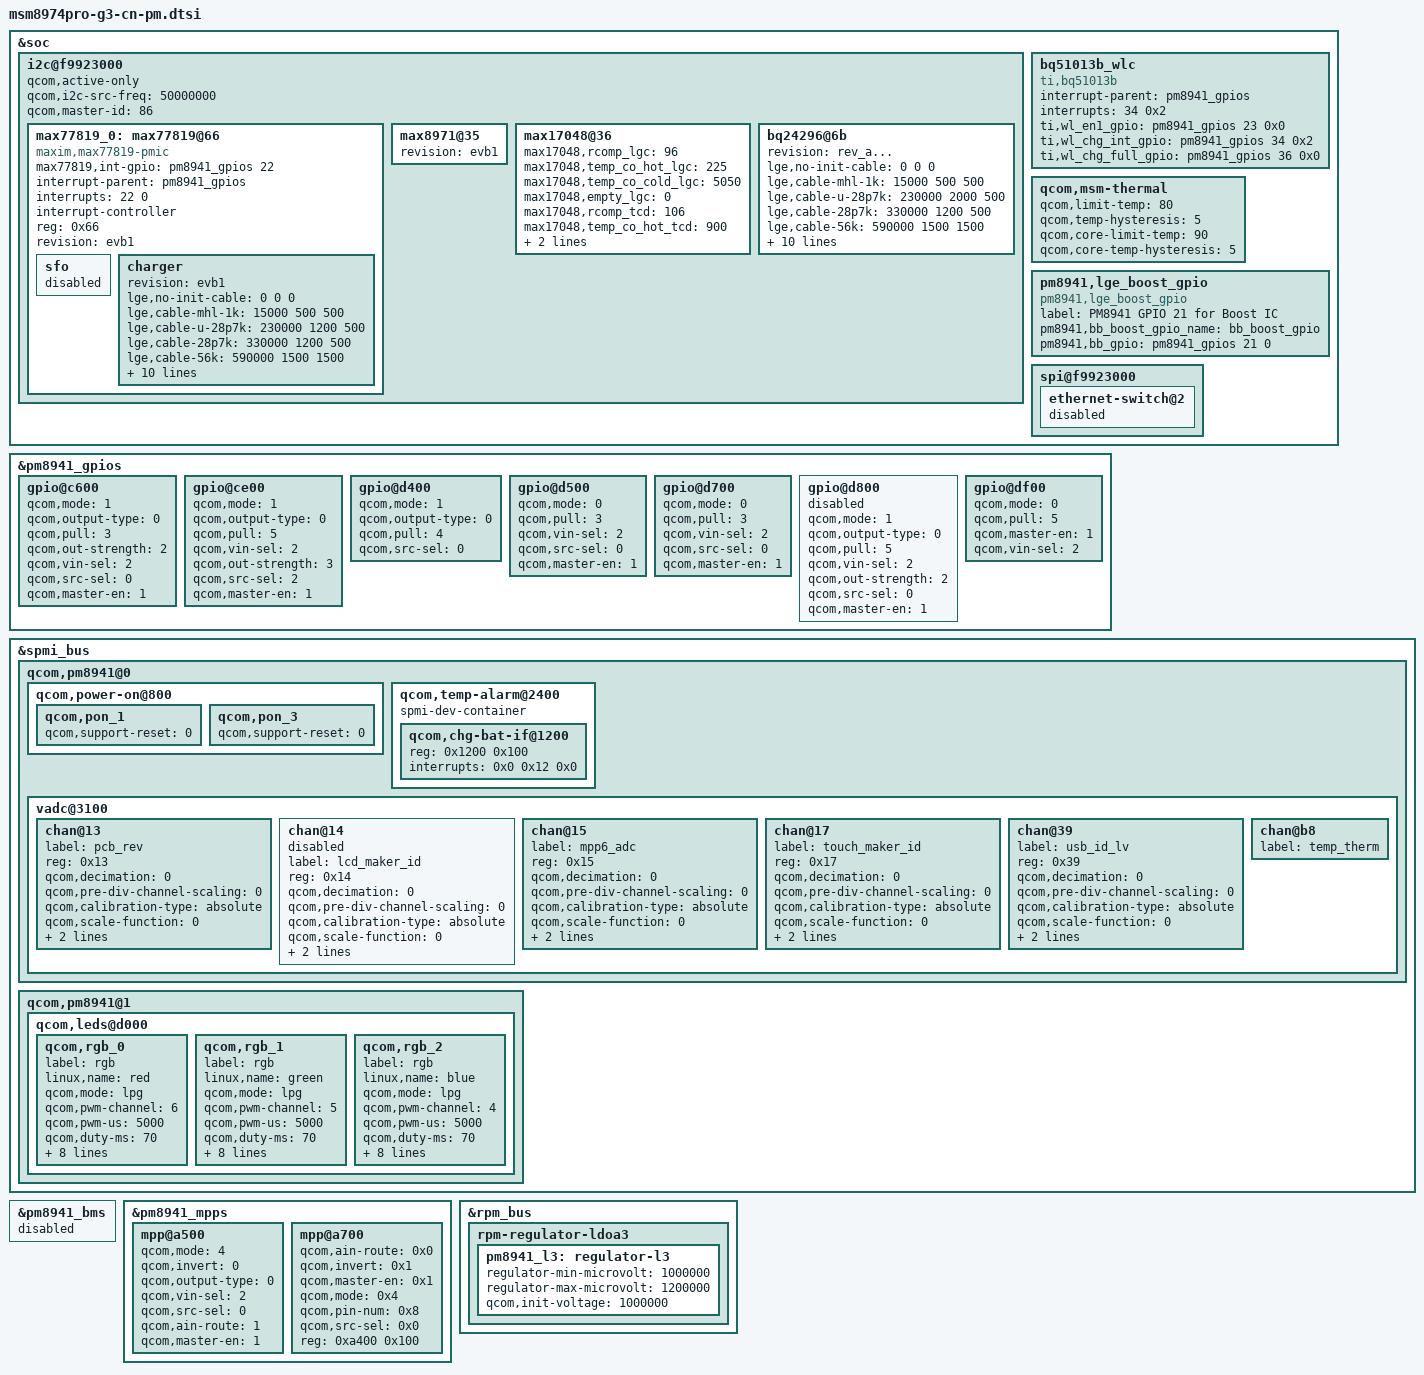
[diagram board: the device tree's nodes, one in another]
/* Copyright (c) 2012, Code Aurora Forum. All rights reserved.
 *
 * This program is free software; you can redistribute it and/or modify
* it under the terms of the GNU General Public License version 2 and
* only version 2 as published by the Free Software Foundation.
*
* This program is distributed in the hope that it will be useful,
* but WITHOUT ANY WARRANTY; without even the implied warranty of
* MERCHANTABILITY or FITNESS FOR A PARTICULAR PURPOSE.  See the
* GNU General Public License for more details.
*/

&soc {
	i2c@f9923000 {
		status = "ok";
		qcom,active-only;
		qcom,i2c-src-freq = <50000000>;
		qcom,master-id = <86>;

		max77819_0: max77819@66 {
			compatible = "maxim,max77819-pmic";
                       #address-cells = <0>;
			max77819,int-gpio = <&pm8941_gpios 22 0x0>;
			interrupt-parent = <&pm8941_gpios>;
			interrupts = <22 0>;
			interrupt-controller;
                       #interrupt-cells = <1>;
			reg = <0x66>;
			status = "ok";
			revision = "evb1";

			sfo {
				status = "disable";
			};

			charger {
				status = "ok";
				revision = "evb1";

				lge,no-init-cable = <0 0 0>;
				lge,cable-mhl-1k = <15000 500 500>;
				lge,cable-u-28p7k = <230000 1200 500>;
				lge,cable-28p7k = <330000 1200 500>;
				lge,cable-56k = <590000 1500 1500>;
				lge,cable-100k = <730000 1200 500>;
				lge,cable-130k = <880000 1500 1500>;
				lge,cable-180k = <1000000 1200 500>;
				lge,cable-200k = <1050000 1200 500>;
				lge,cable-220k = <1110000 1200 500>;
				lge,cable-270k = <1190000 1200 500>;
				lge,cable-330k = <1330000 1200 500>;
				lge,cable-620k = <1480000 1200 500>;
				lge,cable-910k = <1650000 1500 1500>;
				lge,cable-none = <1900000 1800  500>;
			};

		};

		max8971@35 {
			status = "ok";
			revision = "evb1";
		};
		max17048@36 {
			status = "ok";
			max17048,rcomp_lgc = <96>;
			max17048,temp_co_hot_lgc= <225>;
			max17048,temp_co_cold_lgc = <5050>;
			max17048,empty_lgc = <0>;
			max17048,rcomp_tcd = <106>;
			max17048,temp_co_hot_tcd= <900>;
			max17048,temp_co_cold_tcd = <6325>;
			max17048,empty_tcd = <0>;
		};

		bq24296@6b {
			status = "ok";
			revision = "rev_a...";

			lge,no-init-cable = <0 0 0>;
			lge,cable-mhl-1k = <15000 500 500>;
			lge,cable-u-28p7k = <230000 2000 500>;
			lge,cable-28p7k = <330000 1200 500>;
			lge,cable-56k = <590000 1500 1500>;
			lge,cable-100k = <730000 2000 500>;
			lge,cable-130k = <880000 500 1500>;
			lge,cable-180k = <1000000 2000 500>;
			lge,cable-200k = <1050000 2000 500>;
			lge,cable-220k = <1110000 2000 500>;
			lge,cable-270k = <1190000 2000 500>;
			lge,cable-330k = <1330000 2000 500>;
			lge,cable-620k = <1480000 2000 500>;
			lge,cable-910k = <1650000 1500 1500>;
			lge,cable-none = <1900000 2000  500>;
		};
	};

	bq51013b_wlc {
		compatible = "ti,bq51013b";
		status = "ok";
		interrupt-parent = <&pm8941_gpios>;
		interrupts = <34 0x2>;
		ti,wl_en1_gpio = <&pm8941_gpios 23 0x0>;
		ti,wl_chg_int_gpio = <&pm8941_gpios 34 0x2>;
		ti,wl_chg_full_gpio = <&pm8941_gpios 36 0x0>;
	};

	qcom,msm-thermal {
		qcom,limit-temp = <80>;
		qcom,temp-hysteresis = <5>;
		qcom,core-limit-temp = <90>;
		qcom,core-temp-hysteresis = <5>;
	};

	pm8941,lge_boost_gpio {
		compatible = "pm8941,lge_boost_gpio";
		label = "PM8941 GPIO 21 for Boost IC";
		status = "ok";
		pm8941,bb_boost_gpio_name = "bb_boost_gpio";
		pm8941,bb_gpio = <&pm8941_gpios 21 0>;
	};

	spi@f9923000 {
		ethernet-switch@2 {
			status = "disable";
		};
	};
};

/* LGE_CHANGE, yeri.lee@lge.com, 2013-10-31, wm5110 Bring up */
/* GPIO 15, 18 */
&pm8941_gpios {
	gpio@c600 { /* GPIO 7 */
		status = "ok";
		qcom,mode = <1>;
		qcom,output-type = <0>;
		qcom,pull = <3>;
		qcom,out-strength = <2>;
		qcom,vin-sel = <2>;
		qcom,src-sel = <0>;
		qcom,master-en = <1>;
	};

	gpio@ce00 { /* GPIO 15 */
		status = "ok";
		qcom,mode = <1>;
		qcom,output-type = <0>;
		qcom,pull = <5>;
		qcom,vin-sel = <2>;
		qcom,out-strength = <3>;
		qcom,src-sel = <2>;
		qcom,master-en = <1>;
	};

	gpio@d400 { /* GPIO 21 */
		status = "ok";
		qcom,mode = <1>;
		qcom,output-type = <0>;
		qcom,pull = <4>;
		qcom,src-sel = <0>;
	};

	gpio@d500 { /* GPIO 22 */
		status = "ok";                  /* EXT_CHG_INT for bq24296 */
		qcom,mode = <0>;                /* QPNP_PIN_MODE_DIG_IN */
		qcom,pull = <3>;                /* QPNP_PIN_GPIO_PULL_UP_1P5_30 */
		qcom,vin-sel = <2>;             /* QPNP_PIN_VIN2 */
		qcom,src-sel = <0>;             /* QPNP_PIN_SEL_FUNC_CONSTANT */
		qcom,master-en = <1>;
	};

	gpio@d700 { /* GPIO 24 */
		status = "ok";                  /* EXT_CHG_PG for bq24296 */
		qcom,mode = <0>;                /* QPNP_PIN_MODE_DIG_IN */
		qcom,pull = <3>;                /* QPNP_PIN_GPIO_PULL_UP_1P5_30 */
		qcom,vin-sel = <2>;             /* QPNP_PIN_VIN2 */
		qcom,src-sel = <0>;             /* QPNP_PIN_SEL_FUNC_CONSTANT */
		qcom,master-en = <1>;
	};

	gpio@d800 { /* GPIO 25 */
		status = "disable";                  /* rgb_led en for lp5521 */
		qcom,mode = <1>;                /* QPNP_PIN_MODE_DIG_OUT */
		qcom,output-type = <0>;         /* QPNP_PIN_OUT_BUF_CMOS */
		qcom,pull = <5>;                /* QPNP_PIN_PULL_NO */
		qcom,vin-sel = <2>;             /* QPNP_PIN_VIN0 1.8V */
		qcom,out-strength = <2>;        /* QPNP_PIN_OUT_STRENGTH_MED */
		qcom,src-sel = <0>;             /* QPNP_PIN_SEL_FUNC_CONSTANT */
		qcom,master-en = <1>;
	};

	gpio@df00 { 			/* GPIO 32 */
		status = "ok";
		qcom,mode = <0>;	/* QPNP_PIN_MODE_DIG_IN */
		qcom,pull = <5>;	/* QPNP_PIN_PULL_NO */
		qcom,master-en = <1>;   /* Enable Module */
		qcom,vin-sel = <2>;	/* Select 1.8V Source */
	};
};

&spmi_bus {
	qcom,pm8941@0 {
		qcom,power-on@800 {
			qcom,pon_1 {
				status = "ok";
				qcom,support-reset = <0>;
			};
			qcom,pon_3 {
				status = "ok";
				qcom,support-reset = <0>;
			};
		};
		qcom,temp-alarm@2400 {
			spmi-dev-container;
			#address-cells = <1>;
			#size-cells = <1>;
			qcom,chg-bat-if@1200 {
				status = "ok";
				reg = <0x1200 0x100>;
				interrupts =	<0x0 0x12 0x0>;
				interrupt-names = "batt-pres";
			};
		};

		vadc@3100 {
			chan@13 {
				label = "pcb_rev";
				reg = <0x13>;
				qcom,decimation = <0>;
				qcom,pre-div-channel-scaling = <0>;
				qcom,calibration-type = "absolute";
				qcom,scale-function = <0>;
				qcom,hw-settle-time = <0>;
				qcom,fast-avg-setup = <0>;
			};

			chan@14 {
				status = "disable";
				label = "lcd_maker_id";
				reg = <0x14>;
				qcom,decimation = <0>;
				qcom,pre-div-channel-scaling = <0>;
				qcom,calibration-type = "absolute";
				qcom,scale-function = <0>;
				qcom,hw-settle-time = <0>;
				qcom,fast-avg-setup = <0>;
			};

			chan@15 {
				status = "ok";
				label="mpp6_adc";
				reg = <0x15>;
				qcom,decimation = <0>;
				qcom,pre-div-channel-scaling = <0>;
				qcom,calibration-type = "absolute";
				qcom,scale-function = <0>;
				qcom,hw-settle-time = <0>;
				qcom,fast-avg-setup = <0>;
			};

			chan@17 {
				status = "ok";
				label = "touch_maker_id";
				reg = <0x17>;
				qcom,decimation = <0>;
				qcom,pre-div-channel-scaling = <0>;
				qcom,calibration-type = "absolute";
				qcom,scale-function = <0>;
				qcom,hw-settle-time = <0>;
				qcom,fast-avg-setup = <0>;
			};

			chan@39 {
				label = "usb_id_lv";
				reg = <0x39>;
				qcom,decimation = <0>;
				qcom,pre-div-channel-scaling = <0>;
				qcom,calibration-type = "absolute";
				qcom,scale-function = <0>;
				qcom,hw-settle-time = <0>;
				qcom,fast-avg-setup = <0>;
			};

			chan@b8 {
				label = "temp_therm";
			};
		};
	};

	qcom,pm8941@1 {
		qcom,leds@d000 {
			status = "okay";
			qcom,rgb_0 {
				label = "rgb";
				linux,name = "red";
				qcom,mode = "lpg";
				qcom,pwm-channel = <6>;
				qcom,pwm-us = <5000>;
				qcom,duty-ms = <70>;
				qcom,start-idx = <0>;
				qcom,idx-len = <63>;
				qcom,duty-pcts = [
					 00 09 09 00 00
					 00 00 00 15 2A
					 3F 2A 15 00 00
					 00 00 00 00 00
					 00 00 2C 57 5E
					 64 63 63 63 62
					 60 5F 5D 5A 58
					 53 4F 4A 41 37
					 2D 17 00 00 00
					 22 43 2C 16 00
					 00 00 00 00 00
					 09 10 21 31 21
					 10 09 00
					 ];
				qcom,max-current = <12>;
				qcom,default-state = "off";
				qcom,id = <3>;
				linux,default-trigger = "none";
			};

			qcom,rgb_1 {
				label = "rgb";
				linux,name = "green";
				qcom,mode = "lpg";
				qcom,pwm-channel = <5>;
				qcom,pwm-us = <5000>;
				qcom,duty-ms = <70>;
				qcom,start-idx = <0>;
				qcom,idx-len = <63>;
				qcom,duty-pcts = [
					 00 09 09 00 00
					 00 00 00 15 2A
					 3F 2A 15 00 00
					 00 00 00 00 00
					 00 00 2C 57 5E
					 64 63 63 63 62
					 60 5F 5D 5A 58
					 53 4F 4A 41 37
					 2D 17 00 00 00
					 22 43 2C 16 00
					 00 00 00 00 00
					 09 10 21 31 21
					 10 09 00
					 ];
				qcom,max-current = <12>;
				qcom,default-state = "off";
				qcom,id = <4>;
				linux,default-trigger = "none";
			};

			qcom,rgb_2 {
				label = "rgb";
				linux,name = "blue";
				qcom,mode = "lpg";
				qcom,pwm-channel = <4>;
				qcom,pwm-us = <5000>;
				qcom,duty-ms = <70>;
				qcom,start-idx = <0>;
				qcom,idx-len = <63>;
				qcom,duty-pcts = [
					 00 09 09 00 00
					 00 00 00 15 2A
					 3F 2A 15 00 00
					 00 00 00 00 00
					 00 00 2C 57 5E
					 64 63 63 63 62
					 60 5F 5D 5A 58
					 53 4F 4A 41 37
					 2D 17 00 00 00
					 22 43 2C 16 00
					 00 00 00 00 00
					 09 10 21 31 21
					 10 09 00
					 ];
				qcom,max-current = <12>;
				qcom,default-state = "off";
				qcom,id = <5>;
				linux,default-trigger = "none";
			};
		};
      };
};

&pm8941_bms {
	status = "disabled";
};

&pm8941_mpps {
	mpp@a500 { /* MPP 6 */
		status = "ok";
		qcom,mode = <4>;
		qcom,invert = <0>;
		qcom,output-type = <0>;
		qcom,vin-sel = <2>;
		qcom,src-sel = <0>;
		qcom,ain-route = <1>;
		qcom,master-en = <1>;
	};

	mpp@a700 { /* MPP 8 */
		qcom,ain-route = <0x0>;
		qcom,invert = <0x1>;
		qcom,master-en = <0x1>;
		qcom,mode = <0x4>;
		qcom,pin-num = <0x8>;
		qcom,src-sel = <0x0>;
		reg = <0xa400 0x100>;
		status = "ok";
	};
};

&rpm_bus {
	rpm-regulator-ldoa3 {
		pm8941_l3: regulator-l3 {
			regulator-min-microvolt = <1000000>;
			regulator-max-microvolt = <1200000>;
			qcom,init-voltage = <1000000>;
		};
	};
};

